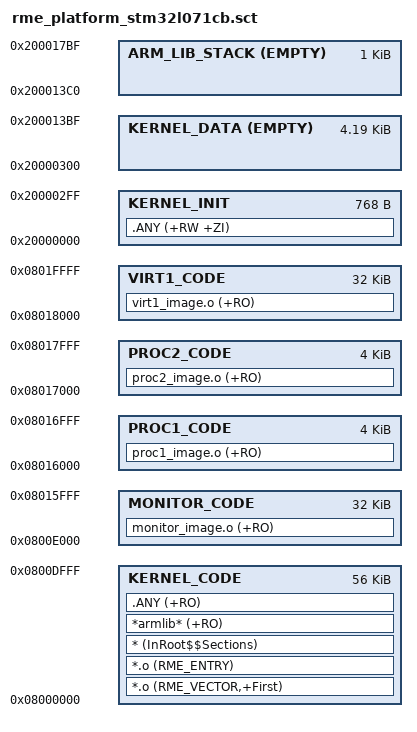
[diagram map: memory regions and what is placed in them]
;******************************************************************************
;Filename    : rme_platform_stm32l071cb.sct
;Author      : The RVM project generator.
;Date        : 05/09/2024 21:43:11
;Licence     : Unlicense; see COPYING for details.
;Description : The scatter file for ARMv7-M layout. This file is intended
;              to be used with STM32L071CB.
;******************************************************************************

;Kernel ***********************************************************************
KERNEL 0x8000000 0xE000
{
    ;Kernel code segment
    KERNEL_CODE 0x8000000 0xE000
    {
        ;The vector table
        *.o                            (RME_VECTOR,+First)
        ;The entry
        *.o                            (RME_ENTRY)
        ;The lib code copying code
        *                              (InRoot$$Sections)
        ;The ARM C library code - all of them is here
        *armlib*                       (+RO)
        ;The kernel code section
        .ANY                           (+RO)
    }

    ;Statically allocated kernel data segment
    KERNEL_INIT 0x20000000 0x300
    {
        .ANY                           (+RW +ZI)
    }

    ;Dynamically allocated kernel data segment
    KERNEL_DATA 0x20000300 EMPTY 0x10C0
    {

    }

    ;Kernel stack segment - required by armlib
    ARM_LIB_STACK 0x200013C0 EMPTY 0x400
    {

    }
}
;End Kernel *******************************************************************

;Monitor **********************************************************************
MONITOR 0x800E000 0x8000
{
    ;Monitor image
    MONITOR_CODE 0x800E000 0x8000
    {
        monitor_image.o                    (+RO)
    }
}
;End Monitor ******************************************************************

;Process **********************************************************************
PROC1 0x8016000 0x1000
{
    ;Process image
    PROC1_CODE 0x8016000 0x1000
    {
        proc1_image.o                   (+RO)
    }
}
;End Process ******************************************************************

;Process **********************************************************************
PROC2 0x8017000 0x1000
{
    ;Process image
    PROC2_CODE 0x8017000 0x1000
    {
        proc2_image.o                   (+RO)
    }
}
;End Process ******************************************************************

;Process **********************************************************************
VIRT1 0x8018000 0x8000
{
    ;Process image
    VIRT1_CODE 0x8018000 0x8000
    {
        virt1_image.o                   (+RO)
    }
}
;End Process ******************************************************************

;End Of File ******************************************************************

;Copyright (C) Evo-Devo Instrum. All rights reserved **************************

